# RL6845_IP_SVD register map
Vendor: Realtek
Registers are 32-bit, read-write, reset 0x0 unless marked. A register's access mark holds for its fields unless they carry their own. Offsets are from the block's base; [hi:lo] are bit positions; lines under a group give offsets from that group; {n}, {i} and the like mark numbered series; <NAME> marks a mode.

## PSRAM_REG
Base 0x40127000
Same registers: SPI_FLASH_CTRL 0x40128000, QSPI_REG 0x40129000
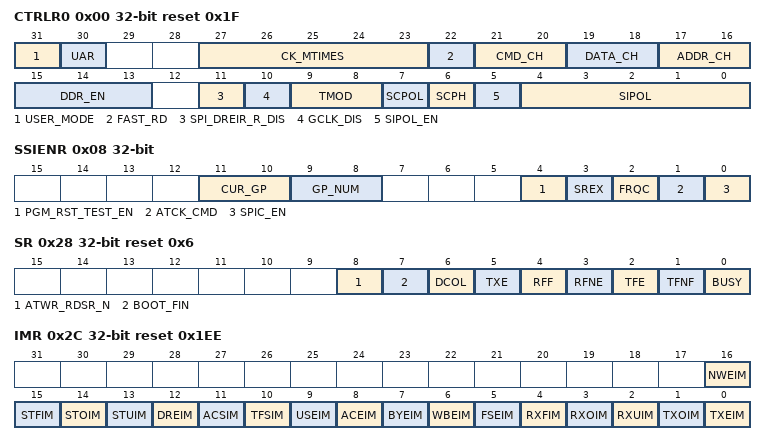
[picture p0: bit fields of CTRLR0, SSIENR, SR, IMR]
0x00 CTRLR0 reset 0x1F — Control Register 0
  [31] USER_MODE — User mode bit. Enable to enter user mode. Disable to enter auto mode. It can not be changed while SPIC is busy (0x28 [0] BUSY). 1: User mode. User can push data to FIFO and set SSIENR to 1. SPIC won't accept auto read/write command. 0: Auto mode. User can't push data to FIFO and set SSIENR to 1. SPIC will accept auto read/write command.
  [30] UAR — User mode bit auto reset. Enable to auto reset USER_MODE to 0 after current user mode transaction is over (SPIC_EN reset to 0).
  [27:23] CK_MTIMES — Indicates the check times. If Flash is always busy in auto-check times, it causes ACEIR interrupt. The delay time (cycles) is related to bus_clk. The cycles of the parameter = (CK_MTIMES << (11+ATCK_BIT_EXTEND).). User should ensure the timeout > Write time of Flash The timeout time(ns) = 2*BAUDR*(1/SPIC_freq)(8/CH) (CK_MTIMES << (11+ATCK_BIT_EXTEND).) Example 1: Flash Program time= 1ms, BAUDR=1, CH=1 (SPI) and (1/SPIC_freq) = 10ns. ATCK_MTIMES should be to set 4. Example 2: SPIC_freq = 200MHz, BAUDR = 1, CH =4 (QSPI), and ATCK_BIT_EXTEND = 2, the maximum auto_check time should be = 2*1*(1/200MHz)(8/4) (5'b11111<<13) = 2*1*(1/200MHz)(8/4) (18'b11_1110_0000_0000_0000) = 2*1*(1/200MHz)(8/4) (18'h3_e000) = 2*1*(1/200MHz)(8/4) (253952) = 5079040 ns = 5.07 ms Suggestion: If ACEIR interrupt occurs, the user should check the flash status by the software itself. Note: Before SVN 8369 Version, CK_MTIMES is fixed to shift 10bit. The formula becomes 2*BAUDR*(1/SPIC_freq)(8/CH) (CK_MTIMES << (10))
  [22] FAST_RD — Indicates to use fast read command in user mode. If setting to 1, SPIC would use FBAUDR to generate spi_sclk.
  [21:20] CMD_CH — Indicates channel number of command phase in transmitting or receiving data. Command phase is usually used to send SPI command. 0: single channel 1: dual channels 2: quad channels 3: octal channel
  [19:18] DATA_CH — Indicates channel number of data phase in transmitting or receiving data. Data phase is used to send data after address phase. 0: single channel 1: dual channels 2: quad channels 3: octal channel
  [17:16] ADDR_CH — Indicates channel number of address phase after command phase. Addr phase is used to send address or data. Addr phase is between one-byte command and a data phase. The number of bytes is determined by the ADDR_LENGTH. 0: single channel 1: dual channels 2: quad channels 3: octal channel
  [15:13] DDR_EN — Indicates the DDR mode in CMD_CH/DATA_CH/ADDR_CH. CTRLR0[15]: CMD_CH (always 2-Byte CMD type) CTRLR0[14]: DATA_CH CTRLR0[13]: ADDR_CH 0: Disable 1: Enable Note: Available only if configuration of DDR_EN is defined.
  [11] SPI_DREIR_R_DIS — Set to disable DR timeout check
  [10] GCLK_DIS — Set to disable gated clock of ICG cell
  [9:8] TMOD — Indicates transfer mode. 2'b00: transmit mode Others (or 2'b11): receive mode
  [7] SCPOL — Indicates serial clock polarity. It is used to select the polarity of the inactive serial clock. 0: inactive state of serial clock is low 1: inactive state of serial clock is high
  [6] SCPH — Indicates serial clock phase. The serial clock phase selects the relationship the serial clock with the slave select signal. 0: serial clock toggles in middle of first data bit 1: serial clock toggles at start of first data bit
  [5] SIPOL_EN — Set to enable SIPOL
  [4:0] SIPOL — While SIPOL_EN = 1: SPI_CS is inactive state (SPI_CS ==1): spi_sin[3:0] = SIPOL[3:0] SPI_CS is active (SPI_CS ==0): spi_sin[3:2] = SIPOL[3:2] (single or dual channel) (SIPOL[4]: reserved for spi_in[7:4])
0x04 RX_NDF — Control Register 1
  [23:0] RX_NDF — Indicates a number of data frames (unit: Byte). When executing receives operation in user mode, SPIC receives data continuously until data frames are equal to RX_NDF.
0x08 SSIENR access per field — SPIC Enable Register
  [11:10] CUR_GP ro — Only used in frequency change function. Used to identify which group register data is internal used. When frqc_req and frqc_ack are both high, CUR_GP will switch to the group which in GP_NUM.
  [9:8] GP_NUM rw — Only used in frequency change function. Set to determine which group register user want to read or write. Base on different operation frequency, some control register setting will change. Therefore we build second group register on USER_LENGTH.USER_RD_DUMMY_LENGTH, AUTO_LENGTH.RD_DUMMY_LENGTH, AUTO_LENGTH.RDSR_DUMMY_LENGTH, AUTO_LENGTH.IN_PHYSICAL_CYC, TPR0.CS_TCEM, TPR0.CS_ACTIVE_HOLD, TPR0.CS_H_WR_DUM_LEN, TPR0.CS_H_RD_DUM_LEN, AUTO_LENGTH2.WR_DUMMY_LENGTH, TPR1.CR_TPWR, TPR1.CR_IDLE_WINDOW, TPR1.CS_ACTICE_SETUP.
  [4] PGM_RST_TEST_EN wo — For PGM RST Test only. Set this bit will generate a pulse as a warm reset signal and run PGM RST flow.
  [3] SREX rw — Set to block auto command before device can be normal accessed after exiting sleep mode. This bit will hold high until timing check counter reaches the set value in CTRLR0.CK_MTIMES.
  [2] FRQC rw — Set to enable frequency change function. SPIC will chop current transaction and then set frqc_req = 1 after setting this bit. Frquency change is finished when frqc_req and frqc_ack are both high and then the choped transaction will return and continue. Write: 0: Not to activate FRQC 1: Activate FRQC Read: 0: FRQC is still in progress 1: FRQC is done
  [1] ATCK_CMD rw — Set to enable ATCK_CMD implementation. After setting SPIC would not accept any command until checking Flash is not busy or checking time out. (Use in User Mode, especially for Erase/Program to check status automatically.) If CTRLR2.SEQ_SET setting, this function needs to disable.
  [0] SPIC_EN rw — Set to enable SPIC and start user mode transaction. SPIC will reset SPIC_EN to 0 after user mode transaction is finished. SPIC_EN can only be set when BOOT_FIN=1 (boot finished) and USER_MODE=1 (user mode). (User can read SPIC_EN to check whether current user mode transaction is finished.)
0x10 SER reset 0x1 — Slave Enable Register
  [0] SER — Each bit in the register corresponds to one SPI Flash. In user mode user program the register to select target flash. 0: Not selected 1: Selected
0x14 BAUDR — Baud Rate Select
  [11:0] SCKDV — Define spi_sclk divider value. The frequency of spi_sclk = The frequency of bus_clk / (2*SCKDV).
0x18 TXFTLR — Transmit FIFO Threshold level
  [4:0] TFT — Transmit FIFO threshold. To Control FIFO entries of valid data in normal transfer except in receiving mode. When a number of FIFO entry is equal or smaller than TFT, SPIC triggers a spi_txeir interrupt. Ex: If TXFTLR = 5'h1, set spi_txeir when FIFO entries <= TFT (0x1)
0x1C RXFTLR — Receive FIFO Threshold level
  [4:0] RFT — Receive FIFO threshold. To Control FIFO entries of valid data in receiving mode. When a number of FIFO entry is greater than RFT, SPIC triggers a spi_rxfir interrupt. Ex: If RXFTLR = 5'h1, set spi_rxfir when FIFO entries > RFT (0x1)
0x20 TXFLR ro — Transmit FIFO level Register
  [5:0] TXFLR — Transmit FIFO level. Indicates the FIFO entry level of valid data in normal mode except in receiving data. (or as FIFO_FLR in any mode)
0x24 RXFLR ro — Receive FIFO level Register
  [5:0] RXFLR — Receive FIFO level. Indicates the FIFO entries of valid data in receiving data.
0x28 SR access per field reset 0x6 — Status Register
  [8] ATWR_RDSR_N rw — The previous auto write cmd didn't check the status register (RDSR). User should check the status register of Flash before next user mode transaction. ATWR_RDSR_N will only be set by SPIC when SEQ_WR_EN = 1.
  [7] BOOT_FIN ro — (Not Yet Ready) Boot Finish. Set if count waiting cycles (Boot Delay Count) for SPI Flash becomes a stable state after power on (or system reset). 1: Boot Finish Note: Auto_mode would be blocked until boot finish. User_mode is allowed with SSIENR inactive before boot finish.
  [6] DCOL ro — Data Collision, or in Transmitting Status. 1: Status shows that SPIC is transmitting spi_flash_cmd/spi_flash_addr/spi_flash_data to SPI Flash. Suggest not reading DR during this transmitting state. (Check this status can avoid reading wrong data and cause SPIC error.)
  [5] TXE ro — Transmission error. Set if FIFO is empty and starting to transmit data to SPI Flash. This bit is cleared when read.
  [4] RFF ro — Receive FIFO full. Set if FIFO is full in receiving mode. This bit is cleared when read.
  [3] RFNE ro — Receive FIFO is not empty. Set if FIFO is not empty in receiving mode. This bit is cleared when read.
  [2] TFE ro — Transmit FIFO is empty. Set if FIFO is empty in transmit mode, else it is cleared when it has data in FIFO.
  [1] TFNF ro — Transmit FIFO is not full. Set if FIFO is not full in transmit mode, else it is cleared when FIFO is full.
  [0] BUSY ro — SPIC busy flag. Set if SPIC is still transmitting to or receiving data from SPI Flash, or TX_FIFO/RX_FIFO are not empty.
0x2C IMR reset 0x1EE — Interrupt Mask Register
  [16] NWEIM — NAND Flash write error interrupt mask. 1: spi_nweir_r is not masked. 0: spi_nweir_r is masked. Note: Available only if configuration of NAND_EN is defined.
  [15] STFIM — Status FIFO full interrupt mask. 1: spi_stfir is not masked. 0: spi_stfir is masked. Note: Available only if configuration of NAND_EN is defined.
  [14] STOIM — Status FIFO overflow interrupt masked. 1: spi_stoir_r is not masked. 0: spi_stoir_r is masked. Note: Available only if configuration of NAND_EN is defined.
  [13] STUIM — Status FIFO underflow interrupt masked. 1: spi_stuir_r is not masked. 0: spi_stuir_r is masked. Note: Available only if configuration of NAND_EN is defined.
  [12] DREIM — DR timeout error interrupt mask. 1: spi_dreir_r is not masked. 0: spi_dreir_r is masked.
  [11] ACSIM — Auto-check Flash Status raw interrupt mask. 1: spi_acsir_r is not masked. 0: spi_acsis_r is masked.
  [10] TFSIM — Transmit finish interrupt mask. 1: spi_tfsir_r is not masked. 0: spi_tfsir_r is masked.
  [9] USEIM — User_mode error interrupt mask. 1: spi_useir_r is not masked. 0: spi_useir_r is masked.
  [8] ACEIM — Auto-check timeout error interrupt mask. 1: spi_aceir_r is not masked. 0: spi_aceir_r is masked.
  [7] BYEIM — The Byte-Enable error interrupt mask. 1: spi_byeir_r is not masked. 0: spi_byeir_r is masked.
  [6] WBEIM — Write burst error interrupt mask. 1: spi_wbier_r is not masked. 0: spi_wbeir_r is masked.
  [5] FSEIM — FIFO size error interrupt mask. 1: spi_fseir_r is not masked. 0: spi_fseir _r is masked
  [4] RXFIM — Receive FIFO full interrupt mask. 1: spi_rxfir is not masked. 0: spi_rxfir is masked.
  [3] RXOIM — Receive FIFO overflow interrupt masked. 1: spi_rxoir_r is not masked. 0: spi_rxoir_r is masked.
  [2] RXUIM — Receive FIFO underflow interrupt masked. 1: spi_rxuir_r is not masked. 0: spi_rxuir_r is masked.
  [1] TXOIM — Transmit FIFO overflow interrupt mask. 1: spi_txoir_r is not masked. 0: spi_txoir_r is masked.
  [0] TXEIM — Transmit FIFO empty interrupt masked. 1: spi_txeir is not masked. 0: spi_txeir is masked.
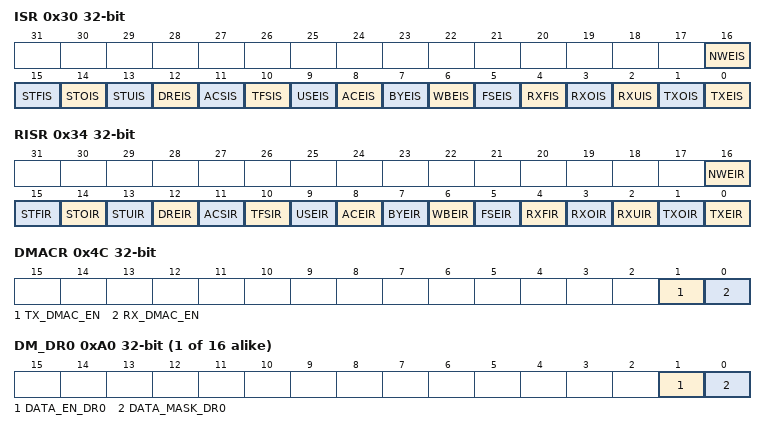
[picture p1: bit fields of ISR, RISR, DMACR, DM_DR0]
0x30 ISR ro — Interrupt Status Register
  [16] NWEIS — NAND Flash write error interrupt status raw interrupt status after masking. 1: spi_nweir_r is active after masking. 0: spi_nweir_r is not active after masking. Note: Available only if configuration of NAND_EN is defined.
  [15] STFIS — Status FIFO full raw interrupt status after masking. 1: spi_stfir_r is active after masking. 0: spi_stfir_r is not active after masking. Note: Available only if configuration of NAND_EN is defined.
  [14] STOIS — Status FIFO overflow interrupt status after masking. 1: spi_stoir_r is active after masking. 0: spi_stoir_r is not active after masking. Note: Available only if configuration of NAND_EN is defined.
  [13] STUIS — Status FIFO underflows interrupt status after masking. 1: spi_stuir_r is active after masking. 0: spi_stuir_r is not active after masking. Note: Available only if configuration of NAND_EN is defined.
  [12] DREIS — DR timeout error status after masking. 1: spi_dreir_r is active after masking. 0: spi_dreir_r is not active after masking.
  [11] ACSIS — Auto-check Flash Status after masking. 1: spi_aceir_r is active after masking. 0: spi_aceir_r is not active after masking.
  [10] TFSIS — Transmit finish interrupt status after masking. 1: spi_tfsir_r is active after masking. 0: spi_tfsir_r is not active after masking.
  [9] USEIS — User mode error status after masking. 1: spi_useir_r is active after masking. 0: spi_useir_r is not active after masking.
  [8] ACEIS — Auto-check timeout error status after masking. 1: spi_aceir_r is active after masking. 0: spi_aceir_r is not active after masking.
  [7] BYEIS — The byte-Enable error interrupts status after masking. 1: spi_byeir_r is active after masking. 0: spi_byeir_r is not active after masking.
  [6] WBEIS — Write burst error interrupt status after masking. 1: spi_wbeir_r is active after masking. 0: spi_wbeir_r is not active after masking.
  [5] FSEIS — FIFO size error interrupts status after masking. 1: spi_fesir_r is active after masking. 0: spi_fesir_r is not active after masking.
  [4] RXFIS — Receive FIFO full interrupt status after masking 1: spi_rxfir is active after masking. 0: spi_rxfir is not active after masking.
  [3] RXOIS — Receive FIFO overflow interrupt status after masking. 1: spi_rxoir_r is active after masking. 0: spi_rxoir_r is not active after masking.
  [2] RXUIS — Receive FIFO underflows interrupt status after masking. 1: spi_rxuir_r is active after masking. 0: spi_rxuir_r is not active after masking.
  [1] TXOIS — Transmit FIFO overflow raw interrupt status after masking. 1: spi_txoir_r is active after masking. 0: spi_txoir_r is not active after masking.
  [0] TXEIS — Transmit FIFO empty raw interrupt status after masking. 1: spi_txeir is active after masking. 0: spi_txeir is not active after masking.
0x34 RISR ro — Raw Interrupt Status Register
  [16] NWEIR — NAND Flash write error interrupt status raw interrupt status prior to masking. 1: spi_nweir_r is active prior to masking. 0: spi_nweir_r is not active prior to masking. Note: Available only if configuration of NAND_EN is defined.
  [15] STFIR — Status FIFO full raw interrupt status prior to masking 1: spi_stfir is active prior to masking. 0: spi_stfir is not active prior to masking. Note: Available only if configuration of NAND_EN is defined.
  [14] STOIR — Status FIFO overflows raw interrupt status prior to masking. 1: spi_stoir_r is active prior to masking. 0: spi_stoir_r is not active prior to masking. Note: Available only if configuration of NAND_EN is defined.
  [13] STUIR — Status FIFO underflows raw interrupt status prior to masking. 1: spi_stuir_r is active prior to masking. 0: spi_stuir_r is not active prior to masking. Note: Available only if configuration of NAND_EN is defined.
  [12] DREIR — DR Timeout error status raw interrupt status prior to masking 1: spi_dreir_r is active prior to masking. 0: spi_dreir_r is not active prior to masking.
  [11] ACSIR — Auto-check Flash Status raw interrupt status prior to masking 1: spi_acsir_r is active prior to masking. 0: spi_acsir_r is not active prior to masking.
  [10] TFSIR — Transmit Finish Status raw interrupt status prior to masking 1: spi_tfsir_r is active prior to masking. 0: spi_tfsir_r is not active prior to masking.
  [9] USEIR — User_mode error status raw interrupt status prior to masking 1: spi_useir_r is active prior to masking. 0: spi_useir_r is not active prior to masking.
  [8] ACEIR — Auto-check timeout error status raw interrupt status prior to masking 1: spi_aceir_r is active prior to masking. 0: spi_aceir_r is not active prior to masking.
  [7] BYEIR — The Byte-Enable error interrupt status raw interrupt status prior to mask. 1: spi_byeir_r is active prior to masking. 0: spi_byeir_r is not active prior to masking.
  [6] WBEIR — Write burst error interrupt status raw interrupt status prior to masking. 1: spi_wbeir_r is active prior to masking. 0: spi_wbeir_r is not active prior to masking.
  [5] FSEIR — FIFO size error interrupt status raw interrupt status prior to masking. 1: spi_fseir_r is active prior to masking. 0: spi_fseir _r is not active prior to masking.
  [4] RXFIR — Receive FIFO full raw interrupt status prior to masking 1:spi_rxfir is active prior to masking. 0: spi_rxfir is not active prior to masking.
  [3] RXOIR — Receive FIFO overflows raw interrupt status prior to masking. 1: spi_rxoir_r is active prior to masking. 0: spi_rxoir_r is not active prior to masking.
  [2] RXUIR — Receive FIFO underflows raw interrupt status prior to masking. 1: spi_rxuir_r is active prior to masking. 0: spi_rxuir_r is not active prior to masking.
  [1] TXOIR — Transmit FIFO overflow raw interrupt status prior to masking. 1: spi_txoir_r is active prior to masking. 0: spi_txoir_r is not active prior to masking.
  [0] TXEIR — Transmit FIFO empty raw interrupt status prior to masking. 1: spi_txeir is active prior to masking. 0: spi_txeir is not active prior to masking.
0x38 TXOICR — Transmit FIFO Overflow Interrupt Clear Register
  [0] TXOICR — When reading/writing the register, spi_rxoir_r would be cleared. Note: Only response value 0x0 when read.
0x3C RXOICR — Receive FIFO Overflow Interrupt Clear Register
  [0] RXOICR — When reading/writing the register, spi_rxoir_r would be cleared. Note: Only response value 0x0 when read.
0x40 RXUICR — Receive FIFO Underflow Interrupt Clear Register
  [0] RXUICR — When reading/writing the register, spi_rxuir_r would be cleared. Note: Only response value 0x0 when read.
0x44 MSTICR — Master error Interrupt Clear Register
  [0] MSTICR — When reading/writing the register, spi_mstir_r would be cleared. Note: Only response value 0x0 when read.
0x48 ICR — Interrupt Clear Register
  [0] ICR — When reading/writing the register, all interrupt would be cleared. Note: Only response value 0x0 when read.
0x4C DMACR — DMA Control Register
  [1] TX_DMAC_EN — Transmit DMA Enable. This bit enables/disables the transmit FIFO DMA channel. 0: Transmit DMA disabled 1: Transmit DMA enabled
  [0] RX_DMAC_EN — Receive DMA Enable. This bit enables/disables the receive FIFO DMA channel 0: Receive DMA disabled 1: Receive DMA enabled
0x50 DMATDLR — DMA Transmit Data Level Register
  [4:0] DMATDL — Transmit Data Level. This bit field controls the level at which a DMA request is made by the transmit logic. It is equal to the watermark level; that is, the dma_tx_req signal is generated when the number of valid data entries in the transmit FIFO is equal to or below this field value, and TDMAE = 1.
0x54 DMARDLR — DMA Receive Data Level Register
  [4:0] DMARDL — Receive Data Level. This bit field controls the level at which a DMA request is made by the receive logic. The watermark level = DMARDL+1; that is, dma_rx_req is generated when the number of valid data entries in the receive FIFO is equal to or above this field value + 1, and RDMAE=1.
0x58 IDR ro — Identification Register
  [31:0] IDCODE — Contain the decimal value of SPIC version.
0x5C SPIC_VERSION ro — SPIC version ID Register
  [31:0] SPIC_VERSION — Contain the decimal value of SPIC version. (After 201612: SVN_NUM changes to Git Counter)
{0x60+4i} DR{i} (i=0..15) — Data Register {i}
  [31:0] DR{i} — It is a data buffer with 8-bit width FIFO. If accessing in word data byte, it would read/write 4 entries of FIFO.
{0xA0+4i} DM_DR{i} wo (i=0..15) — Data Mask Data Register {i}
  [1] DATA_EN_DR{i} — It is a data buffer for spi_data_en signal in user mode. The output value of spi_data_en is the data that has been pushed to DM_FIFO [1]. If DM_FIFO is empty, the output value of spi_data_en will be 0.
  [0] DATA_MASK_DR{i} — It is a data buffer for spi_dm signal in user mode. The output value of spi_dm is the data that has been pushed to DM_FIFO [0]. If DM_FIFO is empty, the output value of spi_data_en will be (~DM_ACT).
0xE0 READ_FAST_SINGLE reset 0xB0B — Fast Read Data Command of SPI Flash
  [15:0] FRD_CMD — Indicate SPI Flash command value of fast read command. The baud rate is used with FBAUDR. FRD_CMD[15:8] is for RD_OCTA_IO_CMD_2nd_BYTE (only available when configuration of DDR_EN is defined) FRD_CMD[7:0] is for RD_OCTA_IO_CMD_1st_BYTE
0xE4 READ_DUAL_DATA reset 0x3B — Dual Output Read Command of SPI Flash
  [7:0] RD_DUAL_O_CMD — Indicates SPI Flash command value of dual data read command.
0xE8 READ_DUAL_ADDR_DATA reset 0xBB — Dual I/O Read Command of SPI Flash
  [7:0] RD_DUAL_IO_CMD — Indicates SPI Flash command value of dual address and data read command.
0xEC READ_QUAD_DATA reset 0x6B — Qaud Output Read Command of SPI Flash
  [7:0] RD_QUAD_O_CMD — Indicates SPI Flash command value of quad data read command.
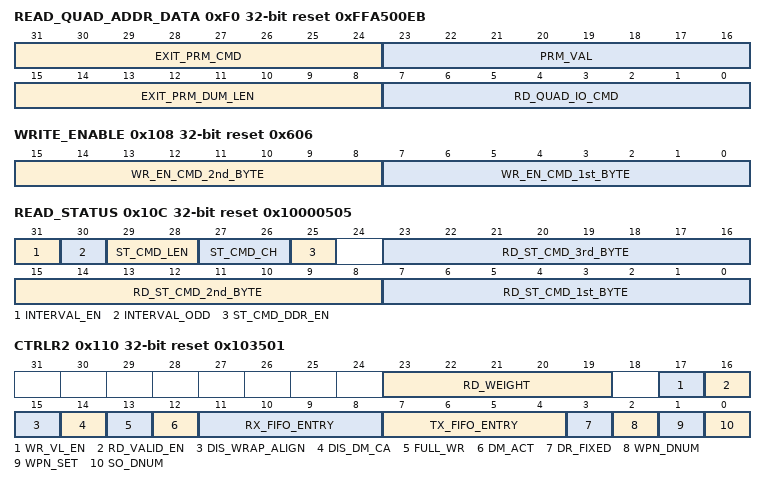
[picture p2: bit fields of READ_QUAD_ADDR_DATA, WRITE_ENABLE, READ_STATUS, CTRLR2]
0xF0 READ_QUAD_ADDR_DATA reset 0xFFA500EB — Quad I/O Read Command of SPI Flash
  [31:24] EXIT_PRM_CMD — Exit High Performance Read Mode commend. Note: Available only if configuration of PRM_EN is defined (SPIC Lite ver).
  [23:16] PRM_VAL — High Performance Read Mode Value. Note: Available only if configuration of PRM_EN is defined (SPIC Lite ver).
  [15:8] EXIT_PRM_DUM_LEN — If Exit PRM commend is more than 1 byte, use EXIT_PRM_DUM_LEN to extend the commend. It is referenced by bus_clk. Ex. In qpi mode (4-4-4), FFFFFFFFh data cycle should be issued (4-byte data in 8 spi cycles). EXIT_PRM_CMD only push 1 byte (2 spi cycles), so use EXIT_PRM_DUM_LEN to extend 6 spi cycles. EXIT_PRM_DUM_LEN = 6 (spi_cycle) * (2 * baurd_rate) Note: Available only if configuration of PRM_EN is defined (SPIC Lite ver).
  [7:0] RD_QUAD_IO_CMD — Indicates SPI Flash command value of quad address and data read command.
0xF4 WRITE_SIGNLE reset 0x202 — Page Program Command of SPI Flash
  [15:0] WR_CMD — Indicate SPI Flash command value of write command. WR_CMD[15:8] is for WR_OCTA_IO_CMD_2nd_BYTE (only available when configuration of DDR_EN is defined) WR_CMD[7:0] is for WR_OCTA_IO_CMD_1st_BYTE
0xF8 WRITE_DUAL_DATA reset 0xA2 — Dual Data Input Program Command of SPI Flash
  [7:0] WR_DUAL_I_CMD — Indicates SPI Flash command value of dual data write command.
0xFC WRITE_DUAL_ADDR_DATA — Dual Address and Data Output Read Command of SPI Flash
  [7:0] WR_DUAL_II_CMD — Indicates SPI Flash command value of dual address and data write command.
0x100 WRITE_QUAD_DATA reset 0x32 — Quad Data Input Program Command of SPI Flash
  [7:0] WR_QUAD_I_CMD — Indicates SPI Flash command value of quad data write command.
0x104 WRITE_QUAD_ADDR_DATA reset 0x38 — Quad Address and Data Output Read Command of SPI Flash
  [7:0] WR_QUAD_II_CMD — Indicates SPI Flash command value of quad address and data write command.
0x108 WRITE_ENABLE reset 0x606 — Write Enable Command of SPI Flash
  [15:8] WR_EN_CMD_2nd_BYTE — Indicates SPI Flash command value of 2nd byte of write enable. Note: Available only if configuration of DDR_EN is defined.
  [7:0] WR_EN_CMD_1st_BYTE — Indicates SPI Flash command value of 1st byte of write enable.
0x10C READ_STATUS reset 0x10000505 — Read Status Command of SPI Flash
  [31] INTERVAL_EN — Set to enable INTERVAL_ODD. Note: Available only if configuration of SPIC_LITE is not defined (SPIC Full ver).
  [30] INTERVAL_ODD — Indicates SPI Flash read status with 2-Byte status but checking only odd byte or even byte. 0: even byte (2, 4, 6, ...) 1: odd byte (1, 3, 5, ...) Note: Available only if configuration of SPIC_LITE is not defined (SPIC Full ver).
  [29:28] ST_CMD_LEN — Indicates the number of bytes in read status command. ST_CMD_LEN can be 1~3. Note: Available only if configuration of SPIC_LITE is not defined (SPIC Full ver).
  [27:26] ST_CMD_CH — Indicates channel number of read status command in transmitting and receiving data. 0: single channel 1: dual channels 2: quad channels 3: octal channel
  [25] ST_CMD_DDR_EN — Indicates the DDR mode in ST_CMD_CH. Note: Available only if configuration of DDR_EN is defined.
  [23:16] RD_ST_CMD_3rd_BYTE — Indicates SPI Flash command value of 3rd byte of read status. Note: Available only if configuration of SPIC_LITE is not defined (SPIC Full ver).
  [15:8] RD_ST_CMD_2nd_BYTE — Indicates SPI Flash command value of 2nd byte of read status. Note: Available only if configuration of SPIC_LITE is not defined (SPIC Full ver).
  [7:0] RD_ST_CMD_1st_BYTE — Indicates SPI Flash command value of 1st byte of read status.
0x110 CTRLR2 reset 0x103501 — Control Register 2
  [23:19] RD_WEIGHT — Set to determine the read and write priority. RD_WEIGHT should >= 2 (if set to 0 or 1, RD_WEIGHT will use the previous value). Ex: if RD_WEIGHT = 5, SPIC will accept 1 write cmd after accepting 4 read cmd.
  [17] WR_VL_EN — Set to enable variable write latency. SPIC will set variable write latency according to RWDS. If WR_VL_EN = 0, SPIC will set fix write latency.
  [16] RD_VALID_EN — Set to enable variable read latency. SPIC will not sample read data until rx_data_valid = 1. If RD_VALID_EN = 0, SPIC will sample read data according to internal counter.
  [15] DIS_WRAP_ALIGN — Set to disable wrap_align function (convert wrap to incremental through aligning start address to burst boundary) in auto mode. If DIS_WRAP_ALIGN = 1, SPIC will chop wrap transation into two incremental transactions.
  [14] DIS_DM_CA — Set to disable spi_dm_oe_n (let the device to drive DM) when SPIC pushing CMD and ADDR for both user mode and auto mode.
  [13] FULL_WR — Set to enable full write in auto mode. If FULL_WR = 0, SPIC will use spi_dm to do the partial write. Note: Available only if configuration of DM_EN is defined.
  [12] DM_ACT — DM (Data Mask) is active high or low, which is defined by specific PSRAM SPEC. If DM is active high (DM=1 means "don't write"), DM_ACT should be set to 1 and the corresponding byte of write data will not be written into the PSRAM. Note: Available only if configuration of DM_EN is defined.
  [11:8] RX_FIFO_ENTRY — If using SPIC_HAS_DMA (NO_MERGE_FIFO) SPIC, this field indicates the valid entry of RX FIFO. It is an index of 2 and it should be equal or smaller than 5. The user can modify it to profile with a different entry. Ex: if RX_FIFO entry is 32, RX_FIFO_ENTYR <=5.
  [7:4] TX_FIFO_ENTRY — If using SPIC_HAS_DMA (NO_MERGE_FIFO) SPIC, this field indicates the valid entry of TX_FIFO. If using MERGE_FIFO SPIC, there is only one FIFO is in the SPIC design, and this field indicates the valid entry of the FIFO. It is an index of 2 and it should be equal or smaller than FIFO_ABW. The user can modify it to profile with a different entry. Ex: if FIFO entry is 32, FIFO_ENTYR <=5.
  [3] DR_FIXED — Indicate the AXI FIXED read mode on DR. If setting 1, user mode read DR will be FIXED. Otherwise, user mode read DR will be INCR.
  [2] WPN_DNUM — Indicates the WPn input pin of SPI Flash is connected to spi_sout[2]or [3]. If setting 0, it connects to spi_sdata[2]. Otherwise, it connects to spi_sdata[3].
  [1] WPN_SET — To implement write protect function. spi_wen_out and the bit of spi_sout which connects to WPN would be initial to 0. WPN_SET: If setting 1 is protected. Otherwise, is not protected.(Configuration Form is using "WPN_SET_n": If setting 1 is NOT protected. Otherwise, is protected.)
  [0] SO_DNUM — Indicates SO input pin of SPI Flash is connected to spi_sout[0]or [1]. It refers to SPI Flash and also the system connection with SPI_Flash (see 6.1.3) If setting 0, it connects to spi_sout[0] (single-channel connection). Otherwise, it connects to spi_sout[1] (multi-channels connection). (Default is configured to 1to support multi-channel connection)
0x114 FBAUDR reset 0x1 — Fast Baud Rate Select
  [11:0] FSCKDV — Indicates the divider of Fast read command when FAST_RD is setting in user mode or using fast read command in auto mode. The frequency of spi_sclk is derived from: Frequency of spi_sclk = Frequency of bus_clk / (2*FSCKDV).
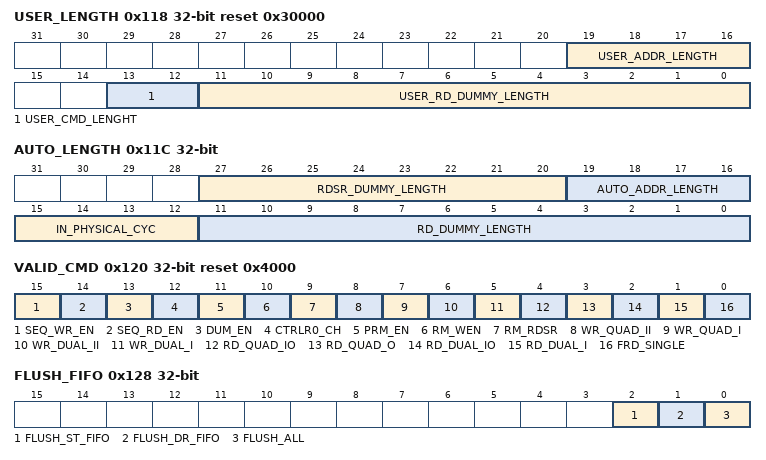
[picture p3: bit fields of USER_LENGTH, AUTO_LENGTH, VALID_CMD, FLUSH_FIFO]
0x118 USER_LENGTH reset 0x30000
  [19:16] USER_ADDR_LENGTH — Indicates number of bytes in address phase (between command phase and write/read phase) in user mode. If it is set to 4, it will transmit 4-byte Address to support 4-byte address mode in SPI Flash.
  [13:12] USER_CMD_LENGHT — Indicates number of bytes in command phase in user mode. USER_CMD_LENGHT can be 0~3.
  [11:0] USER_RD_DUMMY_LENGTH — Indicates delay cycles for receiving data in user mode (USER_MODE == 1). It is referenced by bus_clk.
0x11C AUTO_LENGTH — Auto Address Length Register
  [27:20] RDSR_DUMMY_LENGTH — Indicates delay cycles for receiving data after Read Status Register (RDSR) command. (auto write or user mode with auto check) It is referenced by bus_clk.
  [19:16] AUTO_ADDR_LENGTH — Indicates number of bytes address in read/write command in auto mode. AUTO_ADDR_LENGTH should be 1, 2, 3, 4 bytes. If it is set to 4, it will transmit 4-byte Address to support 4-byte address mode in SPI Flash. Note: PRM in auto mode should set VALID_CMD[11] (PRM_EN) with correct AUTO_ADDR_LENGTH.
  [15:12] IN_PHYSICAL_CYC — Indicates how many SPIC CLK (bus_clk) cycles from pad to internal SPIC.
  [11:0] RD_DUMMY_LENGTH — Indicates delay cycles for receiving data. It is referenced by bus_clk. Note: Don't include SPIC CLK (bus_clk) cycles from pad to internal SPIC
0x120 VALID_CMD reset 0x4000 — Valid Command Register
  [15] SEQ_WR_EN — Set (1) to enable read sequential transaction write function in auto mode. If two bus write transactions are sequential (address is consecutive), SPIC can access second transaction data without sending Read CMD/ADDR/DUMMY. Once disable (0) this bit field, spi_csn will inactive immediately and also disable this function. Note: Run SEQ_WR_EN after SPIC boot finish.
  [14] SEQ_RD_EN — Set (1) to enable read sequential transaction read function in auto mode. If two bus read transactions are sequential (address is consecutive), SPIC can access second transaction data without sending Read CMD/ADDR/DUMMY. Once disable (0) this bit field, spi_csn will inactive immediately and also disable this function. Note: Run SEQ_RD_EN after SPIC boot finish.
  [13] DUM_EN — Enable to push one dummy byte (DUM_BYTE_VAL) after pushing address to Flash in auto read. If PRM_EN is active, it will push PRM_Value instead of DUM_BYTE_VAL. If RD_DUMMY_LENGTH = 0, it won't push the dummy byte.
  [12] CTRLR0_CH — Set (1) to use CTRLR0 CMD_CH/DATA_CH/ADDR_CH and DDR_EN field in Auto mode; Otherwise, SPIC will decode according to which VALID_CMD you choose in auto mode. Suggestion while use this bit field: Read Flash mode: (1-4-8), (4-4-8), (1-4D-8D), (4-4D-8D) with using RD_QUAD_IO[7:0] Read Flash mode (with 2-Byte CMD): (1-8-8), (8-8-8), (8D-8D-8D), (4D-4D-4D) with using RD_FAST_SINGLE_IO[15:0] (always using FBAUD) Write Flash mode: (1-4-8), (4-4-8) with using WR_QUAD_IO[7:0] Write Flash mode (with 2-Byte CMD): (1-8-8), (8-8-8), (8D-8D-8D) with using WR_SINGLE_IO[15:0]
  [11] PRM_EN — Set to enable SPIC performance read mode in Auto Mode. RXI-312 SPIC will auto exit performance read mode before auto write or enter to user mode. Enter PRM Flow: Set CR_VALID_CMD[11] (PRM_EN) with CR_VALID_CMD[4] (RD_QUAD_IO) or with (CR_VALID_CMD[0] and CR_VALID_CMD[12]) Set CR_READ_QUAD_ADDR_DATA[23:16] (PRM_VALUE) and [7:0] (RD_QUAD_IO_CMD) Set correct Dummy Cycle, and Valid Command then access in Auto Mode address range If PRM_EN, at 1st time Auto Rd, it will access with CMD, and store this condition. At 2nd Auto Rd or later, it will access without CMD but with Address and Mode Value. Our SPIC will check PRM_VALUE (CR_READ_QUAD_ADDR_DATA [23:16]), if PRM_VALUE ==0x00 (not a valid PRM value), and PRM_EN is set, SPIC will always access SPI Flash with (CMD+ADDR+MODE+DUMMY+...) format.
  [10] RM_WEN — Remove write enable command in auto write.
  [9] RM_RDSR — Remove read status register in auto write.
  [8] WR_QUAD_II — Indicates quad address/data write is a valid command to execute. (known as (1-4-4))
  [7] WR_QUAD_I — Indicates quad data write is a valid command to execute. (known as (1-1-4))
  [6] WR_DUAL_II — Indicates dual address/data write is a valid command to execute. (known as (1-2-2))
  [5] WR_DUAL_I — Indicates dual data write is a valid command to execute. (known as (1-1-2))
  [4] RD_QUAD_IO — Indicates quad address/data read is a valid command to execute. (known as (1-4-4))
  [3] RD_QUAD_O — Indicates quad data read is a valid command to execute. (known as (1-1-4))
  [2] RD_DUAL_IO — Indicates dual address/data read is a valid command to execute. (known as (1-2-2))
  [1] RD_DUAL_I — Indicates dual data read is a valid command to execute. (known as (1-1-2))
  [0] FRD_SINGLE — Indicates fast read command is a valid command to execute. (known as (1-1-1))
0x124 FLASE_SIZE — Flash Size Register
  [4:0] FLASH_SIZE — Indicates the size of flash to select the target SPI Flash in auto mode. The number is an exponent of 2 (Flash size) -12 (the smallest flash size is 4kB). Ex: If flash size is 4MB (22-bit), set FLASH_SIZE = 10 (22-12).
0x128 FLUSH_FIFO wo
  [2] FLUSH_ST_FIFO — Clear all data in the ST_FIFO when writing to FLUSH_ST_FIFO register.
  [1] FLUSH_DR_FIFO — Clear all data in the TX_FIFO and RX_FIFO when writing to FLUSH_DR_FIFOregister.
  [0] FLUSH_ALL — Clear all data in all FIFO (include TX_FIFO, RX_FIFO and ST_FIFO) and reset all FSM when writing to FLUSH_ALL register.
0x12C DUM_BYTE — Dummy byte value
  [7:0] DUM_BYTE_VAL — Push dummy byte value.
0x130 TX_NDF
  [23:0] TX_NDF — Indicates a number of data frames (Unit: Byte). After transmitting command and address, SPIC transmits data continuously until data frames are equal to TX_NDF. TX_NDF can set larger than TX_FIFO size.
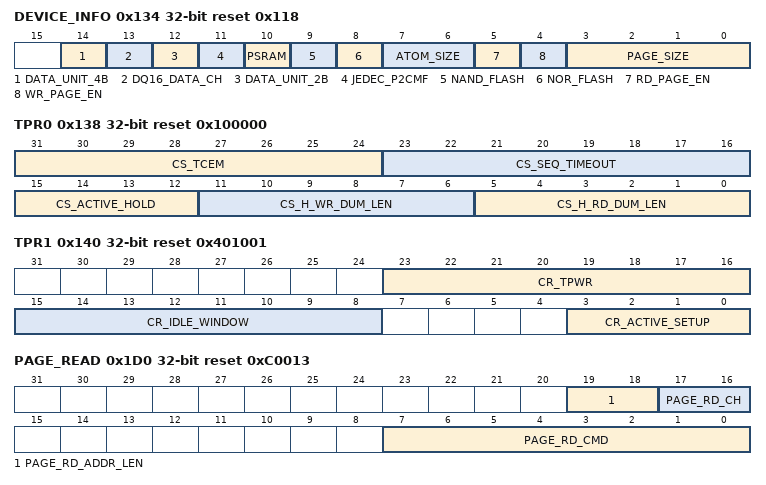
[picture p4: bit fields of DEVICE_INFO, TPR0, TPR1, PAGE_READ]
0x134 DEVICE_INFO access per field reset 0x118
  [14] DATA_UNIT_4B rw — Set (1) when the SPI device stores 4-byte data for each address.
  [13] DQ16_DATA_CH rw — Set (1) when DQ16 PSRAM uses 16-bit data channel. When DQ16_DATA_CH = 1'b1, set CTRLR0[19:18] DATA_CH = 2'b00.
  [12] DATA_UNIT_2B rw — Set (1) when the SPI device stores 2-byte data for each address. Note: Available only if configuration of PSRAM_EN is defined.
  [11] JEDEC_P2CMF rw — Set (1) when the SPI cmd is JEDEC Profile 2.0 Command Modifier Formats. (6-byte command and address) Note: Available only if configuration of PSRAM_EN is defined.
  [10] PSRAM rw — Set (1) when the SPI device is PSRAM. PSRAM will disable WEN and RDSR in auto write. Note: Available only if configuration of PSRAM_EN is defined.
  [9] NAND_FLASH rw — Set (1) when the SPI device is NAND Flash. (not support yet) Note: Available only if configuration of NAND_EN is defined.
  [8] NOR_FLASH rw — Set (1) when the SPI device is NOR Flash.
  [7:6] ATOM_SIZE ro — Set (0) when the atomic size of SPI device is 1-byte. Set (1) when the atomic size of SPI device is 2-byte. (Usually using when OPI and DDR are enabled) Set (2) when the atomic size of SPI device is 4-byte. (Usually using when DQ16 and DDR are enabled) Set (3): reserved
  [5] RD_PAGE_EN rw — Enable SPIC to chop the burst read command across page boundaries in auto mode.
  [4] WR_PAGE_EN rw — Enable SPIC to chop the burst write command across page boundaries in auto mode.
  [3:0] PAGE_SIZE rw — The page size of the SPI device (byte) = 2^(PAGE_SIZE) eg. If the page size of the SPI Flash is 256-byte. PAGE_SIZE should be set to 8.
0x138 TPR0 reset 0x100000 — Timing parameters
  [31:24] CS_TCEM — Set to chop auto cmd when CSN low pulse width = (CS_TCEM*32) bus_clk. If set CS_TCEM = 0 will disable this function. ex. PSRAM tCEM = 4us, SPIC frequency = 100Mhz. CS_TCEM = ((4000 ns/10 ns)/32) - BYTE_DELAY = 12 (0xc) - BYTE_DELAY If ((16*baud_rate)/data_channel) <=32. BYTE_DELAY = 0. If ((16*baud_rate)/data_channel) > 32. BYTE_DELAY = (((16*baud_rate)/data_channel) - 32)/32. ex. If baud_rate = 3, data_channel = 1. BYTE_DELAY = (((16*3)/1) - 32)/32 = 16/32 = 0.5 Therefore, BYTE_DELAY should be 1 in this example. Note: Available only if configuration of PSRAM_EN is defined.
  [23:16] CS_SEQ_TIMEOUT — The timeout setting of auto command after sequential read command. If set CS_SEQ_TIMEOUT = 0x00 will disable this function. If set CS_SEQ_TIMEOUT > 0x00, SPIC will exit sequential transaction read and inactive CS when there is no auto read/write command for (CS_SEQ_TIMEOUT *4) bus_clocks.
  [15:12] CS_ACTIVE_HOLD — For Flash chip select active hold time after SCLK rising edge (refer to tSLCH/CHSH, tCSS/tCSH) Note: Wait most 16 bus_clk cycles before CS inactive. (Implement CS_ACTIVE_Hold timing only, CS_ACTIVE_Setup timing using D-PHY to shift)
  [11:6] CS_H_WR_DUM_LEN — Dummy cycle between sending write command to SPI Flash. Using the dummy cycles to avoid the timing violation of CS high time.
  [5:0] CS_H_RD_DUM_LEN — Dummy cycle between sending read command to SPI Flash. Using the dummy cycles to avoid the timing violation of CS high time.
0x13C AUTO_LENGTH2 — Auto Address Length Register 2
  [11:0] WR_DUMMY_LENGTH — Indicates delay cycles for transmitting data in auto mode. It is referenced by bus_clk. Note: Available only if configuration of PSRAM_EN is defined.
0x140 TPR1 reset 0x401001 — Timing Parameters Register 1
  [23:16] CR_TPWR — It is used to configure the cycle counts before spi_csn becomes low when spi_pwr turns from low to high
  [15:8] CR_IDLE_WINDOW — It is used to configure the cycle counts before turn off the spi_pwr when SPIC is IDLE.
  [3:0] CR_ACTIVE_SETUP — It is used to configure the setup time before the first edge (rising edge for mode0 and falling edge for mode3) of spi_sclk(refer to tCSS or tSLCH ). Note: It can't be configured 0x0 (if you configure 0x0 to this 4 bits field, this field will not be updated).
{0x180+4i} ST_DR{i} ro (i=0..15) — Status Data Register {i}
  [7:0] ST_DR{i} — It is a data buffer with 8-bit width FIFO.
0x1C0 STFLR ro — Status FIFO level Register
  [3:0] STFLR — Status FIFO level. Indicates the FIFO entries of valid data in status data. Note: Available only if configuration of NAND_EN is defined.
0x1D0 PAGE_READ reset 0xC0013 — Page Read Command of NAND Flash
  [19:18] PAGE_RD_ADDR_LEN — Indicates number of bytes in address phase in page read command. Note: Available only if configuration of NAND_EN is defined.
  [17:16] PAGE_RD_CH — Indicates channel number of command and address phase in transmitting page read command. 0: single channel 1: dual channels 2: quad channels 3: octal channel Note: Available only if configuration of NAND_EN is defined.
  [7:0] PAGE_RD_CMD — Indicates SPI Flash command value of page read command Note: Available only if configuration of NAND_EN is defined.
